# WS53 register map
File version: 0.1.0-experimental
Registers are 32-bit, read-write, no defined reset value unless marked. A register's access mark holds for its fields unless they carry their own. Offsets are from the block's base; [hi:lo] are bit positions; {n}, {i} and the like mark numbered series.

## UART0
Base 0x52081000
Same registers: UART1 0x52080000, UART2 0x57014000
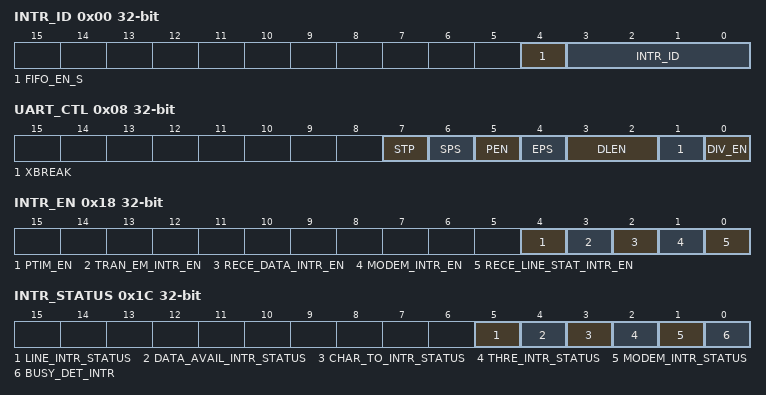
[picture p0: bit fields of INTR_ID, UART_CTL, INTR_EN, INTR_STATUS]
0x00 INTR_ID ro read-modifies
  [4] FIFO_EN_S — FIFO enable status: 0=FIFO disabled; 1=FIFO enabled
  [3:0] INTR_ID read-has-side-effects — Interrupt ID: 0=modem, 1=none, 2=TX, 4=RX, 6=line error, 7=busy, 12=RX timeout. Reading ID 2 acknowledges its TX request; UART2 observed 2 then 1 in both PTIM modes. Other causes have their own acknowledgement. UART0/1 TX read-clear behavior is not physically qualified.
0x04 RX ro read-has-side-effects
  [7:0] DATA read-has-side-effects — Pop one byte from RX FIFO; not a passive read
0x04 TX wo (alternate view of RX)
  [7:0] DATA — Push one byte into TX FIFO
0x08 UART_CTL
  [7] STP — Stop duration: 0=one bit; 1=one-and-a-half bits when DLEN=0 (five data bits), otherwise two bits. Source configuration semantics, not waveform timing proof.
    0=Stop1 (1 stop bit); 1=Stop1_5_or_2 (1.5 (5-bit data) or 2 stop bits)
  [6] SPS — Sticky parity: 0=disabled; 1=enabled
  [5] PEN — Parity enable: 0=disabled; 1=enabled
    0=Disabled (No parity); 1=Enabled (Parity enabled)
  [4] EPS — Parity select: 0=odd; 1=even
    0=Odd (Odd parity); 1=Even parity
  [3:2] DLEN — Data length: 00=5bit; 01=6bit; 10=7bit; 11=8bit
    {v}=Bits{v+5} ({v+5}-bit data) (v=0..3)
  [1] XBREAK — Break control: 0=normal; 1=force TX to space
  [0] DIV_EN — A-board: set only after RX is drained; attempted set with1/2/64 queued bytes reads back clear. Other control-bit acceptance and TX-only busy behavior unqualified.
0x0C DIV_H range 0..255
  [7:0] DIV_H — Integer divider high byte. SDK opens DIV_EN before reading; high-byte hardware gating has not been established.
0x10 DIV_L range 0..255
  [7:0] DIV_L — Integer divider low byte. A-board UART0/1/2 reads zero with DIV_EN clear and the programmed value when set. Setting DIV_EN while RX has queued bytes does not latch; drain RX before enabling. High-byte and divisor-write gating remain unqualified.
0x14 DIV_FRA
  [5:0] DIV_FRA — Divider fractional part (divided by 2^6)
0x18 INTR_EN
  [4] PTIM_EN — Programmable THRE interrupt mode enable
  [3] TRAN_EM_INTR_EN — TX empty interrupt enable
  [2] RECE_DATA_INTR_EN — RX data available interrupt enable
  [1] MODEM_INTR_EN — Modem status interrupt enable
  [0] RECE_LINE_STAT_INTR_EN — RX line status interrupt enable
0x1C INTR_STATUS ro
  [5] LINE_INTR_STATUS — RX line interrupt status
  [4] DATA_AVAIL_INTR_STATUS — RX data available interrupt status
  [3] CHAR_TO_INTR_STATUS — Character timeout interrupt status
  [2] THRE_INTR_STATUS — THR empty interrupt status
  [1] MODEM_INTR_STATUS — Modem interrupt status
  [0] BUSY_DET_INTR — Busy detect interrupt status
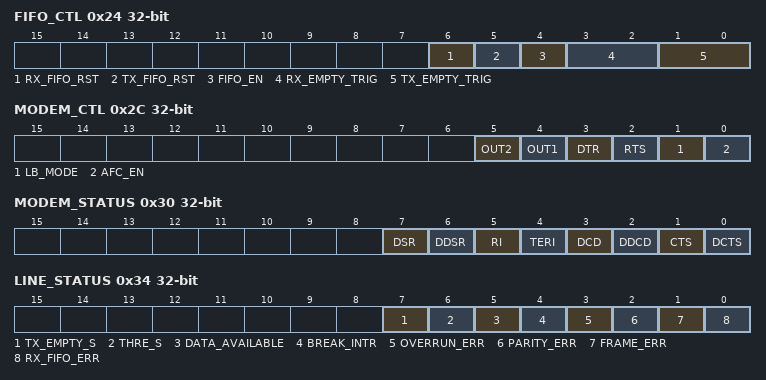
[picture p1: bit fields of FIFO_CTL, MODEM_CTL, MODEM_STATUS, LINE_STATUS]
0x24 FIFO_CTL wo
  [6] RX_FIFO_RST — RX FIFO reset: 0=no reset; 1=reset
  [5] TX_FIFO_RST — TX FIFO reset: 0=no reset; 1=reset
  [4] FIFO_EN — FIFO enable
  [3:2] RX_EMPTY_TRIG — RX trigger: 00=1char; 01=1/4; 10=1/2; 11=2below full
    0=Char1 (1 character in FIFO); 1=Quarter (FIFO 1/4 full); 2=Half (FIFO 1/2 full); 3=Less2 (2 below full)
  [1:0] TX_EMPTY_TRIG — TX empty trigger: 00=empty; 01=2chars; 10=1/4; 11=1/2
    0=Empty (FIFO empty); 1=Chars2 (2 characters remaining); 2=Quarter (FIFO 1/4 full); 3=Half (FIFO 1/2 full)
0x28 FAR
  [0] FAR — FIFO access mode: 0=disabled; 1=enabled
0x2C MODEM_CTL
  [5] OUT2
  [4] OUT1
  [3] DTR
  [2] RTS — RTS software control
  [1] LB_MODE — Loopback mode: 0=disabled; 1=enabled
  [0] AFC_EN — Auto flow control enable
0x30 MODEM_STATUS ro read-modifies
  [7] DSR
  [6] DDSR read-clears
  [5] RI
  [4] TERI read-clears
  [3] DCD
  [2] DDCD read-clears
  [1] CTS — CTS signal state
  [0] DCTS read-clears — CTS change indicator
0x34 LINE_STATUS ro read-modifies
  [7] TX_EMPTY_S — Transmitter empty flag
  [6] THRE_S — SDK: with PTIM and FIFO enabled, 1 means TX FIFO full; otherwise 1 means THR/FIFO empty. UART2 observed both polarities. This is not transmitter-shift-register completion; use TX_EMPTY_S for line drain.
  [5] DATA_AVAILABLE — Data available in RX FIFO/RBR
  [4] BREAK_INTR — Break interrupt
  [3] OVERRUN_ERR read-clears — Overrun error
  [2] PARITY_ERR read-clears — Parity error
  [1] FRAME_ERR read-clears — Framing error
  [0] RX_FIFO_ERR read-modifies — Read can clear only when the errored character is at FIFO head and no later errors remain
0x38 UART_GP_REG
  [7:0] UART_GP_REG — General purpose storage
0x3C TX_FIFO_READ ro read-has-side-effects
  [7:0] TX_FIFO_READ read-has-side-effects — TX FIFO top data
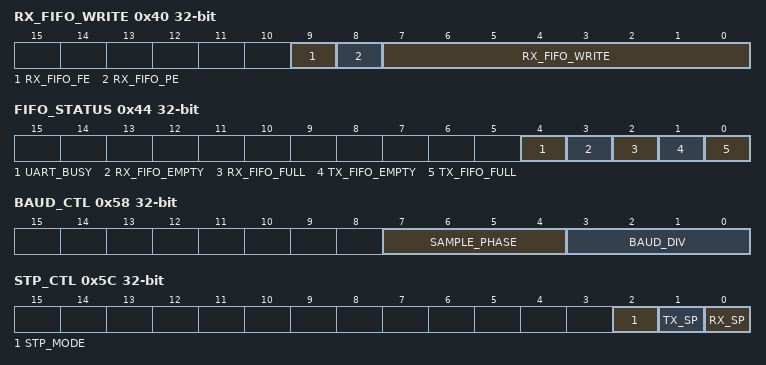
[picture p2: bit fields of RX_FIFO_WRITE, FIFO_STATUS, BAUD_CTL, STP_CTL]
0x40 RX_FIFO_WRITE wo
  [9] RX_FIFO_FE — RX FIFO framing error
  [8] RX_FIFO_PE — RX FIFO parity error
  [7:0] RX_FIFO_WRITE — Push test data only in FIFO access mode; no read-level alias established on WS53
0x44 FIFO_STATUS ro
  [4] UART_BUSY — A-board UART0/1/2: high with1/2/64 clean queued RX bytes, low after draining. SDK PRO calls this busy; TX-only and disabled-FIFO behavior unqualified.
  [3] RX_FIFO_EMPTY — A-board: asserted when enabled RX FIFO is empty; clear at1/2/64 bytes and after H1/H0 soft reset with FIFO disabled. SDK comment incorrectly calls this full.
  [2] RX_FIFO_FULL — A-board: asserted at64 queued RX bytes, clear at0/1/2. SDK non-PRO comment incorrectly calls this not-empty.
  [1] TX_FIFO_EMPTY — TX FIFO empty flag
  [0] TX_FIFO_FULL — TX FIFO full flag
0x48 TX_FIFO_CNT ro
  [6:0] TX_FIFO_LEVEL — TX FIFO data count
0x4C RX_FIFO_CNT ro
  [6:0] RX_FIFO_LEVEL — Receive FIFO data count
0x50 HALT_TX
  [0] HALT_TX — TX halt: 0=disabled; 1=enabled
0x54 DMA_SW_ACK wo
  [0] DMA_SW_ACK — DMA software acknowledge (write-clear)
0x58 BAUD_CTL
  [7:4] SAMPLE_PHASE — RX sample phase
  [3:0] BAUD_DIV — Baud rate oversampling: 0x7=8x; 0xF=16x
    7=Div8 (8x oversampling); 15=Div16 (16x oversampling)
0x5C STP_CTL
  [2] STP_MODE — Stop bit control mode: 0=UART_CTL stp; 1=STP_CTL
  [1] TX_SP — TX stop bits when stp_mode=1
  [0] RX_SP — RX stop bits when stp_mode=1
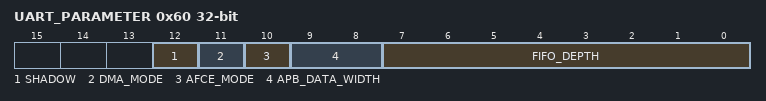
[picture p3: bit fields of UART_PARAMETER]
0x60 UART_PARAMETER ro
  [12] SHADOW — Shadow feature enable
  [11] DMA_MODE — DMA mode: 0=DMA_EXTRA disabled; 1=enabled
  [10] AFCE_MODE — AFCE mode: 0=disabled; 1=enabled
  [9:8] APB_DATA_WIDTH — APB data width: 0x1=16bit
  [7:0] FIFO_DEPTH — FIFO depth: 0x4=64
